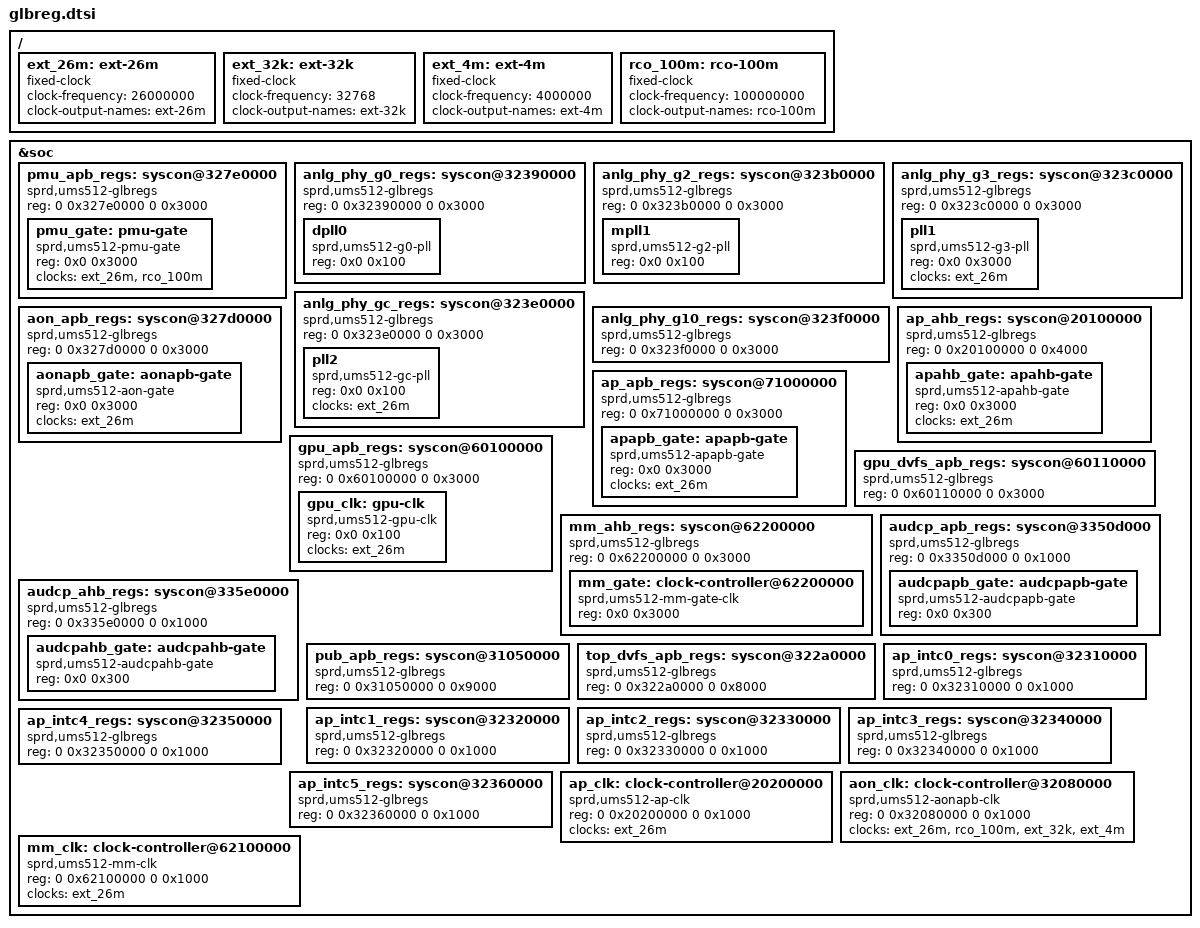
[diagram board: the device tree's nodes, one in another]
// SPDX-License-Identifier: (Licenseref-Unisoc-General-1.0 OR GPL-2.0-only)
/*
 * glbreg.dtsi - Unisoc platform device
 *
 * Copyright 2022 Unisoc(Shanghai) Technologies Co.Ltd
 *
 * Licensed under the Unisoc General Software License, version 1.0 (the
 * License);
 * you may not use this file except in compliance with the License.
 * You may obtain a copy of the License at
 * https://www.unisoc.com/en_us/license/UNISOC_GENERAL_LICENSE_V1.0-EN_US
 * Software distributed under the License is distributed on an "AS IS" BASIS,
 * WITHOUT WARRANTIES OF ANY KIND, either express or implied.
 * See the Unisoc General Software License, version 1.0 for more details.
 *
 * Alternatively you can use and distribute this file under the terms of the
 * GNU General Public License version 2, provided that it has to be used
 *  (including but not limited to combining, linking) with any other file under
 * the GNU General Public License version 2 on platforms that use Unisoc Chips.
 */

#include <dt-bindings/soc/sprd,sharkl5pro-regs.h>
#include <dt-bindings/soc/sprd,sharkl5pro-mask.h>

&soc {
	pmu_apb_regs: syscon@327e0000 {
		compatible = "sprd,ums512-glbregs", "syscon",
			     "simple-mfd";
		reg = <0 0x327e0000 0 0x3000>;
		#address-cells = <1>;
		#size-cells = <1>;
		ranges = <0 0 0x327e0000 0x3000>;

		pmu_gate: pmu-gate {
			compatible = "sprd,ums512-pmu-gate";
			reg = <0x0 0x3000>;
			clocks = <&ext_26m>, <&rco_100m>;
			clock-names = "ext-26m", "rco-100m";
			#clock-cells = <1>;
			#reset-cells = <1>;
		};
	};

	anlg_phy_g0_regs: syscon@32390000 {
		compatible = "sprd,ums512-glbregs", "syscon",
			     "simple-mfd";
		reg = <0 0x32390000 0 0x3000>;
		#address-cells = <1>;
		#size-cells = <1>;
		ranges = <0 0 0x32390000 0x3000>;

		dpll0: dpll0 {
			compatible = "sprd,ums512-g0-pll";
			reg = <0x0 0x100>;
			#clock-cells = <1>;
		};
	};

	anlg_phy_g2_regs: syscon@323b0000 {
		compatible = "sprd,ums512-glbregs", "syscon",
			     "simple-mfd";
		reg = <0 0x323b0000 0 0x3000>;
		#address-cells = <1>;
		#size-cells = <1>;
		ranges = <0 0 0x323b0000 0x3000>;

		mpll1: mpll1 {
			compatible = "sprd,ums512-g2-pll";
			reg = <0x0 0x100>;
			#clock-cells = <1>;
		};
	};

	anlg_phy_g3_regs: syscon@323c0000 {
		compatible = "sprd,ums512-glbregs", "syscon",
			     "simple-mfd";
		reg = <0 0x323c0000 0 0x3000>;
		#address-cells = <1>;
		#size-cells = <1>;
		ranges = <0 0 0x323c0000 0x3000>;

		pll1: pll1 {
			compatible = "sprd,ums512-g3-pll";
			reg = <0x0 0x3000>;
			clocks = <&ext_26m>;
			clock-names = "ext-26m";
			#clock-cells = <1>;
		};
	};

	anlg_phy_gc_regs: syscon@323e0000 {
		compatible = "sprd,ums512-glbregs", "syscon",
			     "simple-mfd";
		reg = <0 0x323e0000 0 0x3000>;
		#address-cells = <1>;
		#size-cells = <1>;
		ranges = <0 0 0x323e0000 0x3000>;

		pll2: pll2 {
			compatible = "sprd,ums512-gc-pll";
			reg = <0x0 0x100>;
			clocks = <&ext_26m>;
			clock-names = "ext-26m";
			#clock-cells = <1>;
		};
	};

	anlg_phy_g10_regs: syscon@323f0000 {
		compatible = "sprd,ums512-glbregs", "syscon",
			     "simple-mfd";
		reg = <0 0x323f0000 0 0x3000>;
	};

	aon_apb_regs: syscon@327d0000 {
		compatible = "sprd,ums512-glbregs", "syscon",
			     "simple-mfd";
		reg = <0 0x327d0000 0 0x3000>;
		#address-cells = <1>;
		#size-cells = <1>;
		ranges = <0 0 0x327d0000 0x3000>;

		aonapb_gate: aonapb-gate {
			compatible = "sprd,ums512-aon-gate";
			reg = <0x0 0x3000>;
			clocks = <&ext_26m>;
			clock-names = "ext-26m";
			#clock-cells = <1>;
			#reset-cells = <1>;
		};
	};

	ap_ahb_regs: syscon@20100000 {
		compatible = "sprd,ums512-glbregs", "syscon",
			     "simple-mfd";
		reg = <0 0x20100000 0 0x4000>;
		#address-cells = <1>;
		#size-cells = <1>;
		ranges = <0 0 0x20100000 0x4000>;

		apahb_gate: apahb-gate {
			compatible = "sprd,ums512-apahb-gate";
			reg = <0x0 0x3000>;
			clocks = <&ext_26m>;
			clock-names = "ext-26m";
			#clock-cells = <1>;
			#reset-cells = <1>;
		};
	};

	ap_apb_regs: syscon@71000000 {
		compatible = "sprd,ums512-glbregs", "syscon",
			     "simple-mfd";
		reg = <0 0x71000000 0 0x3000>;
		#address-cells = <1>;
		#size-cells = <1>;
		ranges = <0 0 0x71000000 0x3000>;

		apapb_gate: apapb-gate {
			compatible = "sprd,ums512-apapb-gate";
			reg = <0x0 0x3000>;
			clocks = <&ext_26m>;
			clock-names = "ext-26m";
			#clock-cells = <1>;
			#reset-cells = <1>;
		};
	};

	gpu_apb_regs: syscon@60100000 {
		compatible = "sprd,ums512-glbregs", "syscon",
			     "simple-mfd";
		reg = <0 0x60100000 0 0x3000>;
		#address-cells = <1>;
		#size-cells = <1>;
		ranges = <0 0 0x60100000 0x3000>;

		gpu_clk: gpu-clk {
			compatible = "sprd,ums512-gpu-clk";
			reg = <0x0 0x100>;
			clocks = <&ext_26m>;
			clock-names = "ext-26m";
			#clock-cells = <1>;
			#reset-cells = <1>;
		};
	};

	gpu_dvfs_apb_regs: syscon@60110000 {
		compatible = "sprd,ums512-glbregs", "syscon",
			     "simple-mfd";
		reg = <0 0x60110000 0 0x3000>;
	};

	mm_ahb_regs: syscon@62200000 {
		compatible = "sprd,ums512-glbregs", "syscon",
			     "simple-mfd";
		reg = <0 0x62200000 0 0x3000>;
		#address-cells = <1>;
		#size-cells = <1>;
		ranges = <0 0 0x62200000 0x3000>;

		mm_gate: clock-controller@62200000 {
			compatible = "sprd,ums512-mm-gate-clk";
			reg = <0x0 0x3000>;
			#clock-cells = <1>;
			#reset-cells = <1>;
		};
	};

	audcp_apb_regs: syscon@3350d000 {
		compatible = "sprd,ums512-glbregs", "syscon",
			     "simple-mfd";
		reg = <0 0x3350d000 0 0x1000>;
		#address-cells = <1>;
		#size-cells = <1>;
		ranges = <0 0 0x3350d000 0x1000>;

		audcpapb_gate: audcpapb-gate {
			compatible = "sprd,ums512-audcpapb-gate";
			reg = <0x0 0x300>;
			#clock-cells = <1>;
			#reset-cells = <1>;
		};
	};

	audcp_ahb_regs: syscon@335e0000 {
		compatible = "sprd,ums512-glbregs", "syscon",
			     "simple-mfd";
		reg = <0 0x335e0000 0 0x1000>;
		#address-cells = <1>;
		#size-cells = <1>;
		ranges = <0 0 0x335e0000 0x1000>;

		audcpahb_gate: audcpahb-gate {
			compatible = "sprd,ums512-audcpahb-gate";
			reg = <0x0 0x300>;
			#clock-cells = <1>;
			#reset-cells = <1>;
		};
	};

	pub_apb_regs: syscon@31050000 {
		compatible = "sprd,ums512-glbregs", "syscon",
			     "simple-mfd";
		reg = <0 0x31050000 0 0x9000>;
	};

	top_dvfs_apb_regs: syscon@322a0000 {
		compatible = "sprd,ums512-glbregs", "syscon",
			     "simple-mfd";
		reg = <0 0x322a0000 0 0x8000>;
	};

	ap_intc0_regs: syscon@32310000 {
		compatible = "sprd,ums512-glbregs", "syscon",
			     "simple-mfd";
		reg = <0 0x32310000 0 0x1000>;
	};

	ap_intc1_regs: syscon@32320000 {
		compatible = "sprd,ums512-glbregs", "syscon",
			     "simple-mfd";
		reg = <0 0x32320000 0 0x1000>;
	};

	ap_intc2_regs: syscon@32330000 {
		compatible = "sprd,ums512-glbregs", "syscon",
			     "simple-mfd";
		reg = <0 0x32330000 0 0x1000>;
	};

	ap_intc3_regs: syscon@32340000 {
		compatible = "sprd,ums512-glbregs", "syscon",
			     "simple-mfd";
		reg = <0 0x32340000 0 0x1000>;
	};

	ap_intc4_regs: syscon@32350000 {
		compatible = "sprd,ums512-glbregs", "syscon",
			     "simple-mfd";
		reg = <0 0x32350000 0 0x1000>;
	};

	ap_intc5_regs: syscon@32360000 {
		compatible = "sprd,ums512-glbregs", "syscon",
			     "simple-mfd";
		reg = <0 0x32360000 0 0x1000>;
	};

	/* Clock node */
	ap_clk: clock-controller@20200000 {
		compatible = "sprd,ums512-ap-clk";
		reg = <0 0x20200000 0 0x1000>;
		clocks = <&ext_26m>;
		clock-names = "ext-26m";
		#clock-cells = <1>;
	};

	aon_clk: clock-controller@32080000 {
		compatible = "sprd,ums512-aonapb-clk";
		reg = <0 0x32080000 0 0x1000>;
		clocks = <&ext_26m>, <&rco_100m>, <&ext_32k>,
			 <&ext_4m>;
		clock-names = "ext-26m", "rco-100m", "ext-32k",
			      "ext-4m";
		#clock-cells = <1>;
	};

	mm_clk: clock-controller@62100000 {
		compatible = "sprd,ums512-mm-clk";
		reg = <0 0x62100000 0 0x1000>;
		clocks = <&ext_26m>;
		clock-names = "ext-26m";
		#clock-cells = <1>;
	};
};

/ {
	ext_26m: ext-26m {
		compatible = "fixed-clock";
		#clock-cells = <0>;
		clock-frequency = <26000000>;
		clock-output-names = "ext-26m";
	};

	ext_32k: ext-32k {
		compatible = "fixed-clock";
		#clock-cells = <0>;
		clock-frequency = <32768>;
		clock-output-names = "ext-32k";
	};

	ext_4m: ext-4m {
		compatible = "fixed-clock";
		#clock-cells = <0>;
		clock-frequency = <4000000>;
		clock-output-names = "ext-4m";
	};

	rco_100m: rco-100m {
		compatible = "fixed-clock";
		#clock-cells = <0>;
		clock-frequency = <100000000>;
		clock-output-names = "rco-100m";
	};
};
